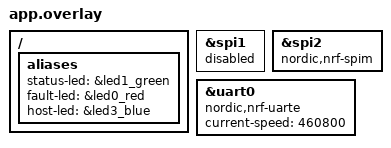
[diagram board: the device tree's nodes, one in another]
/ {
	aliases {
		/* D9: green user LED on DWM1001-DEV, active-low (nRF P0.30). */
		status-led = &led1_green;
		/* D8 red: radio/platform fault. */
		fault-led = &led0_red;
		/* D11 blue: valid host command received (GUI heartbeat). */
		host-led = &led3_blue;
	};
};

/*
 * The application talks to the internal DW1000 through SPI2.  SPI1 only goes
 * to the DWM1001-DEV Raspberry Pi header and is unused by this TAG firmware.
 * Disable it so the external header pins remain quiescent during bring-up.
 */
&spi1 {
	status = "disabled";
};

/*
 * DW1000 bus. The board file selects the legacy "nordic,nrf-spi", which
 * interrupts the CPU after every byte: measured on 2026-09-26, the TAG spent
 * up to ~0.8 ms of SPI work per processing step, a large part of each 3.9 ms
 * ranging slot. The EasyDMA SPIM moves a whole register access per transfer.
 * uwb_platform_spi_xfer() sends header and data as one buffer, so no 1-byte
 * transfer can hit nRF52832 anomaly 58 (Zephyr also enables its workaround).
 */
&spi2 {
	compatible = "nordic,nrf-spim";
};

/*
 * UART0 uses P0.05/P0.11.  With factory-default solder bridges J14/J15 closed,
 * it is exposed as the on-board J-Link USB Virtual COM port.
 *
 * RANGE_MEAS sends one 66-byte frame per measurement next to the per-cycle
 * snapshot. Measured with eight anchors (29 Hz cycle): ~20 kB/s, far beyond
 * 115200 baud (11.5 kB/s), so UART0 uses the EasyDMA UARTE at 460800
 * (~46 kB/s, 44 % load; RANGE_MEAS needs >= 460800).
 *
 * Not 1 Mbaud: on 2026-09-26 the J-Link OB-STM32F072 VCOM of this board
 * delivered the bytes at 1 Mbaud but 72 % of them failed CRC, with and
 * without its MSD disabled. Long and back-to-back frames never arrived.
 * The GUI and uwb_command.py default to 460800.
 */
&uart0 {
	compatible = "nordic,nrf-uarte";
	current-speed = <460800>;
	status = "okay";
};
